# FUSB15200 register map
Vendor: ON Semiconductor; Series: FUSB15200; File version: 1.0
ARM 32-bit Cortex-M0+ Microcontroller based device, CPU clock up to 24MHz.
CPU: CM0+ r1p0, little endian, no MPU, no FPU, 3 interrupt priority bits
Registers are 32-bit, read-write, reset 0x0 unless marked. A register's access mark holds for its fields unless they carry their own. Offsets are from the block's base; lines under a group give offsets from that group; [hi:lo] are bit positions; {n}, {i} and the like mark numbered series; 'fields as' and 'values as' point back to an identical list; <NAME> marks a mode.

## Memory map
0x08000000 NVR1 size 0x1000
0x08000200 NVR2 size 0x1000
0x08000400 NVR3 size 0x1000
0x08000600 NVR4 size 0x1000
0x08000800 NVR5 size 0x1000
0x40000000 Clock_Management_Unit size 0x1000
0x40000070 Power_Management_Unit size 0x1000
0x40100000 WatchDog_Timer_Registers size 0x1000
0x40200000 Timer_0 size 0x1000
0x40300000 Timer_1 size 0x1000
0x40400000 Wake_Up_Timer size 0x1000
0x40500000 NTC_Port_A_B_Interface size 0x1000
0x40700000 PORT_Interface size 0x1000
0x40800000 GPIO_Interface size 0x1000
0x40900000 ADC_Interface size 0x1000
0x40A00000 DMA size 0x1000
0x40C00000 I2C_Port_1 size 0x1000
0x40D00000 I2C_Port_2 size 0x1000
0x40E00000 I2C_Port_3 size 0x1000
0x40F00000 I2C_Port_4 size 0x1000
0x41900000 USB_Type_C_PD_Port_A size 0x1000
0x41A00000 USB_Type_C_PD_Port_B size 0x1000
0x41C00000 Legacy_DP_DM_Protocol_Port_A size 0x1000
0x41D00000 Legacy_DP_DM_Protocol_Port_B size 0x1000
0x41F00000 Flash_Control size 0x1000
0x42100000 TEST size 0x1000
0x42300000 HPD_Port_A size 0x1000
0x42400000 HPD_Port_B size 0x1000
0xE000E010 SYSTICK_Timer_Registers size 0x1000
0xE000E100 Nested_Vector_Interrupt_Controller size 0x1000
0xE000ED00 System_Control_Block size 0x1000

## Clock_Management_Unit
Base 0x40000000
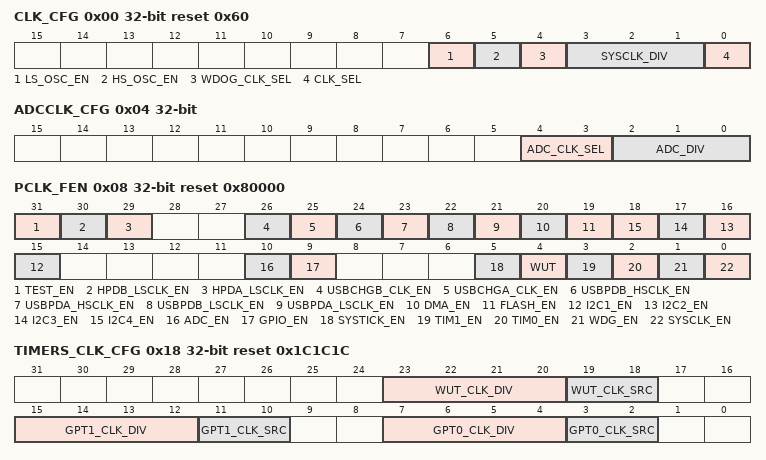
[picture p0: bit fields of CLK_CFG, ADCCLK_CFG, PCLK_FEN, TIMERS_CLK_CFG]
0x00 CLK_CFG reset 0x60 (reset mask 0x73)
  [6] LS_OSC_EN, [5] HS_OSC_EN, [4] WDOG_CLK_SEL, [3:1] SYSCLK_DIV, [0] CLK_SEL
0x04 ADCCLK_CFG (reset mask 0x9)
  [4:3] ADC_CLK_SEL, [2:0] ADC_DIV
0x08 PCLK_FEN reset 0x80000
  [31] TEST_EN, [30] HPDB_LSCLK_EN, [29] HPDA_LSCLK_EN, [26] USBCHGB_CLK_EN, [25] USBCHGA_CLK_EN, [24] USBPDB_HSCLK_EN, [23] USBPDA_HSCLK_EN, [22] USBPDB_LSCLK_EN, [21] USBPDA_LSCLK_EN, [20] DMA_EN, [19] FLASH_EN, [n+14] I2C{n}_EN (n=1..4), [10] ADC_EN, [9] GPIO_EN, [5] SYSTICK_EN, [4] WUT, [3] TIM1_EN, [2] TIM0_EN, [1] WDG_EN, [0] SYSCLK_EN
0x10 PD_HSCLK_CFG reset not defined
0x18 TIMERS_CLK_CFG reset 0x1C1C1C (reset mask 0x141414)
  [23:20] WUT_CLK_DIV, [19:18] WUT_CLK_SRC, [15:12] GPT1_CLK_DIV, [11:10] GPT1_CLK_SRC, [7:4] GPT0_CLK_DIV, [3:2] GPT0_CLK_SRC

## Power_Management_Unit
Base 0x40000070
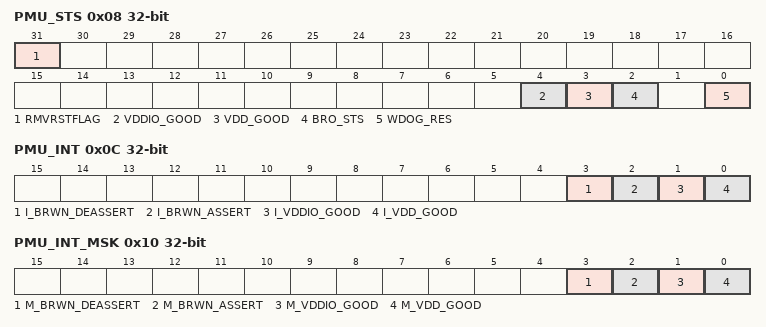
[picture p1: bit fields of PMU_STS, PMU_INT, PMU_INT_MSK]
0x08 PMU_STS
  [31] RMVRSTFLAG wo, [4] VDDIO_GOOD ro, [3] VDD_GOOD ro, [2] BRO_STS ro, [0] WDOG_RES ro
0x0C PMU_INT
  [3] I_BRWN_DEASSERT wo, [2] I_BRWN_ASSERT wo, [1] I_VDDIO_GOOD wo, [0] I_VDD_GOOD wo
0x10 PMU_INT_MSK
  [3] M_BRWN_DEASSERT, [2] M_BRWN_ASSERT, [1] M_VDDIO_GOOD, [0] M_VDD_GOOD

## WatchDog_Timer_Registers
Base 0x40100000
0x00 WDT_LD reset 0xFFFFFFFF (reset mask 0x1)
0x04 WDT_VAL reset 0xFFFFFFFF (reset mask 0x1)
  [31:0] WDT_VAL ro
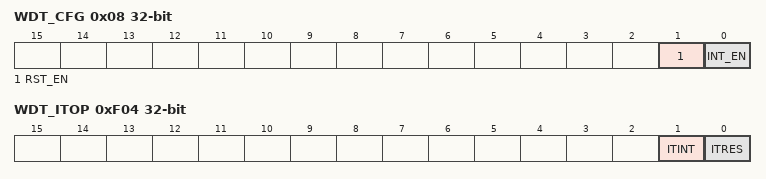
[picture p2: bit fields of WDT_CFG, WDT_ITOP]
0x08 WDT_CFG
  [1] RST_EN, [0] INT_EN
0x0C _WDT_INTCLR (reset mask 0x1)
  [31:0] INTCLR wo
0x10 WDT_INTSTS_RAW
  [0] INT_STS_RAW ro
0x14 WDT_INTSTS
  [0] INT_STS ro
0xC00 WDT_LOCK (reset mask 0x1)
0xF00 WDT_ITCTL
  [0] ITCNTL
0xF04 WDT_ITOP
  [1] ITINT wo, [0] ITRES wo

## Licence text in the file
Copyright 2022 ON Semiconductor. All rights reserved. This software and/or documentation is licensed by ON Semiconductor under limited terms and conditions. The terms and conditions pertaining to the software and/or documentation are available at [ONSMEI_T&C.pdf] ( http://www.onsemi.com/site/pdf/ONSEMI_T&C.pdf ) ("ON Semiconductor Standard Terms and Conditions of Sale, Section 8 Software"). DO NOT USE THIS SOFTWARE AND/OR DOCUMENTATION UNLESS YOU HAVE CAREFULLY. READ AND YOU AGREE TO THE LIMITED TERMS AND CONDITIONS. BY USING THIS

## Notices in the file
Copyright 2020 ON Semiconductor. All rights reserved.
software and/or documentation are available at [ONSEMI_T&C.pdf]
SOFTWARE AND/OR DOCUMENTATION, YOU AGREE TO THE LIMITED TERMS AND CONDITIONS.
THIS SOFTWARE IS PROVIDED BY THE COPYRIGHT HOLDERS AND CONTRIBUTORS "AS IS"
AND ANY EXPRESS OR IMPLIED WARRANTIES, INCLUDING, BUT NOT LIMITED TO, THE
IMPLIED WARRANTIES OF MERCHANTABILITY AND FITNESS FOR A PARTICULAR PURPOSE
ARE DISCLAIMED. IN NO EVENT SHALL COPYRIGHT HOLDERS AND CONTRIBUTORS BE
LIABLE FOR ANY DIRECT, INDIRECT, INCIDENTAL, SPECIAL, EXEMPLARY, OR
CONSEQUENTIAL DAMAGES (INCLUDING, BUT NOT LIMITED TO, PROCUREMENT OF
SUBSTITUTE GOODS OR SERVICES; LOSS OF USE, DATA, OR PROFITS; OR BUSINESS
INTERRUPTION) HOWEVER CAUSED AND ON ANY THEORY OF LIABILITY, WHETHER IN
CONTRACT, STRICT LIABILITY, OR TORT (INCLUDING NEGLIGENCE OR OTHERWISE)
ARISING IN ANY WAY OUT OF THE USE OF THIS SOFTWARE, EVEN IF ADVISED OF THE
POSSIBILITY OF SUCH DAMAGE.
